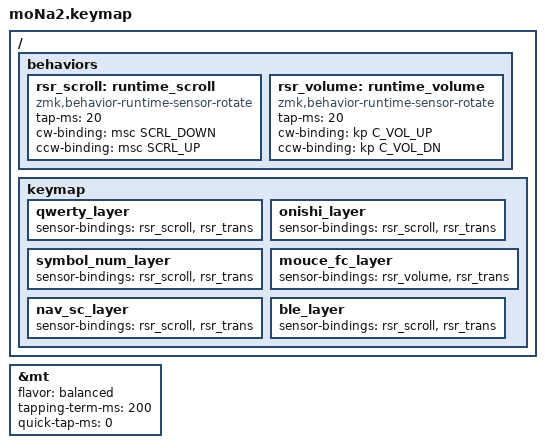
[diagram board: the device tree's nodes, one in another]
/* 添付の6レイヤー・42キーをそのまま使用し、エンコーダー編集を追加。 */
#include <behaviors.dtsi>
#include <dt-bindings/zmk/bt.h>
#include <dt-bindings/zmk/keys.h>
#include <dt-bindings/zmk/outputs.h>
#include <dt-bindings/zmk/pointing.h>
#include <behaviors/runtime_macro.dtsi>
#include <behaviors/runtime-sensor-rotate.dtsi>

&mt {
    flavor = "balanced";
    tapping-term-ms = <200>;
    quick-tap-ms = <0>;
};

#include "keymaps/mona2-2026-10-19.keymap"

/ {
    behaviors {
        rsr_scroll: runtime_scroll {
            compatible = "zmk,behavior-runtime-sensor-rotate";
            #sensor-binding-cells = <0>;
            tap-ms = <20>;
            cw-binding = <&msc SCRL_DOWN>;
            ccw-binding = <&msc SCRL_UP>;
        };
        rsr_volume: runtime_volume {
            compatible = "zmk,behavior-runtime-sensor-rotate";
            #sensor-binding-cells = <0>;
            tap-ms = <20>;
            cw-binding = <&kp C_VOL_UP>;
            ccw-binding = <&kp C_VOL_DN>;
        };
    };
    keymap {
        qwerty_layer { sensor-bindings = <&rsr_scroll &rsr_trans>; };
        onishi_layer { sensor-bindings = <&rsr_scroll &rsr_trans>; };
        symbol_num_layer { sensor-bindings = <&rsr_scroll &rsr_trans>; };
        mouce_fc_layer { sensor-bindings = <&rsr_volume &rsr_trans>; };
        nav_sc_layer { sensor-bindings = <&rsr_scroll &rsr_trans>; };
        ble_layer { sensor-bindings = <&rsr_scroll &rsr_trans>; };
    };
};
